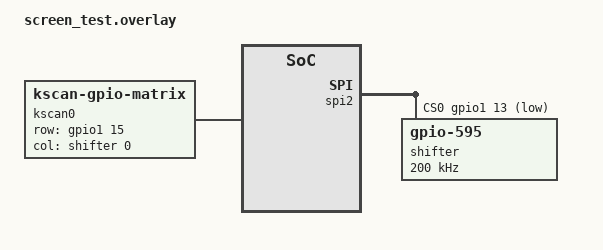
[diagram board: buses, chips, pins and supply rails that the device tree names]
#include <dt-bindings/zmk/matrix_transform.h>

/ {
    chosen {
        zmk,kscan = &kscan0;
        zmk,matrix_transform = &default_transform;
        zephyr,display = &oled;
    };

    default_transform: keymap_transform_0 {
        compatible = "zmk,matrix-transform";
        columns = <1>;
        rows = <1>;
        map = <RC(0,0)>;
    };

    kscan0: kscan_0 {
        compatible = "zmk,kscan-gpio-matrix";
        wakeup-source;
        diode-direction = "col2row";

        row-gpios = <&gpio1 15 (GPIO_ACTIVE_HIGH | GPIO_PULL_DOWN)>;
        col-gpios = <&shifter 0 GPIO_ACTIVE_HIGH>;
    };
};

&spi2 {
    compatible = "nordic,nrf-spim";
    status = "okay";
    pinctrl-0 = <&spi2_default>;
    pinctrl-1 = <&spi2_sleep>;
    pinctrl-names = "default", "sleep";
    cs-gpios = <&gpio1 13 GPIO_ACTIVE_LOW>;

    shifter: 595@0 {
        compatible = "zmk,gpio-595";
        status = "okay";
        gpio-controller;
        spi-max-frequency = <200000>;
        reg = <0>;
        #gpio-cells = <2>;
        ngpios = <8>;
    };
};
